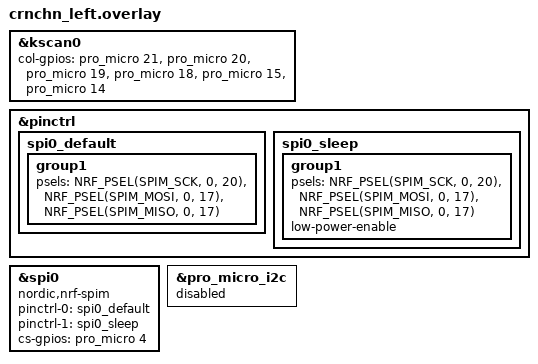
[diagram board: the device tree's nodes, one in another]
#include "crnchn.dtsi"

&kscan0 {
    col-gpios =
        <&pro_micro 21 GPIO_ACTIVE_HIGH>,    // Column 1
        <&pro_micro 20 GPIO_ACTIVE_HIGH>,    // Column 2
        <&pro_micro 19 GPIO_ACTIVE_HIGH>,    // Column 3
        <&pro_micro 18 GPIO_ACTIVE_HIGH>,    // Column 4
        <&pro_micro 15 GPIO_ACTIVE_HIGH>,    // Column 5
        <&pro_micro 14 GPIO_ACTIVE_HIGH>;
};

&pinctrl {
    spi0_default: spi0_default {
        group1 {
            psels = <NRF_PSEL(SPIM_SCK, 0, 20)>,     // SCL D3 P0.20
                <NRF_PSEL(SPIM_MOSI, 0, 17)>,        // SDA D5 P0.17
                <NRF_PSEL(SPIM_MISO, 0, 17)>;        // Reuse MOSI pin (display doesn't send data back)
        };
    };
    spi0_sleep: spi0_sleep {
        group1 {
            psels = <NRF_PSEL(SPIM_SCK, 0, 20)>,     // SCL D3 P0.20
                <NRF_PSEL(SPIM_MOSI, 0, 17)>,        // SDA D5 P0.17
                <NRF_PSEL(SPIM_MISO, 0, 17)>;        // Reuse MOSI pin
            low-power-enable;
        };
    };
};

nice_view_spi: &spi0 {
    compatible = "nordic,nrf-spim";
    pinctrl-0 = <&spi0_default>;
    pinctrl-1 = <&spi0_sleep>;
    pinctrl-names = "default", "sleep";
    cs-gpios = <&pro_micro 4 GPIO_ACTIVE_HIGH>;    // CS D4 P0.22
};

&pro_micro_i2c {
    status = "disabled";
};
